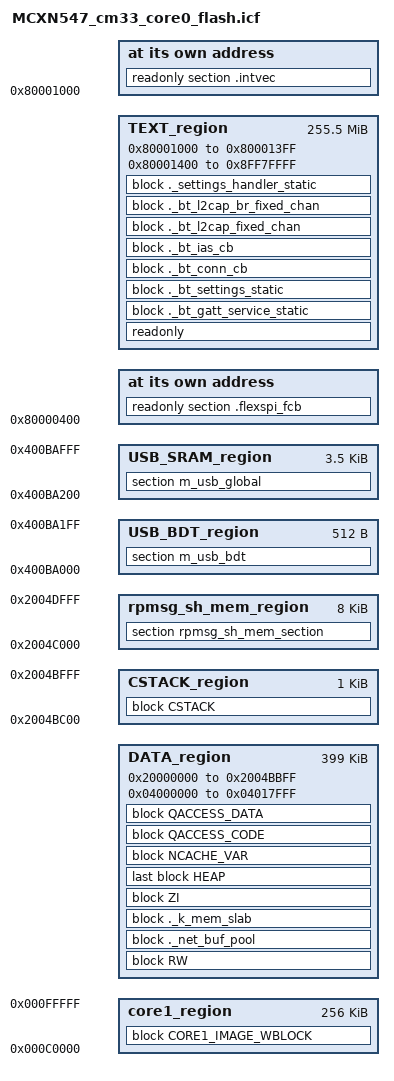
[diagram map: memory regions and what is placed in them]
/*
** ###################################################################
**     Processors:          MCXN547VDF_cm33_core0
**                          MCXN547VNL_cm33_core0
**
**     Compiler:            IAR ANSI C/C++ Compiler for ARM
**     Reference manual:    MCXNx4x Reference Manual
**     Version:             rev. 1.0, 2021-08-03
**     Build:               b230607
**
**     Abstract:
**         Linker file for the IAR ANSI C/C++ Compiler for ARM
**
**     Copyright 2016 Freescale Semiconductor, Inc.
**     Copyright 2016-2023 NXP
**     SPDX-License-Identifier: BSD-3-Clause
**
**     http:                 www.nxp.com
**     mail:                 support@nxp.com
**
** ###################################################################
*/


/* USB BDT size */
define symbol usb_bdt_size             = 0x200;
/* Stack and Heap Sizes */
if (isdefinedsymbol(__stack_size__)) {
  define symbol __size_cstack__        = __stack_size__;
} else {
  define symbol __size_cstack__        = 0x0400;
}

if (isdefinedsymbol(__heap_size__)) {
  define symbol __size_heap__          = __heap_size__;
} else {
  define symbol __size_heap__          = 0x1000;
}

define symbol LITTLEFS_REGION_SIZE               = 0x00080000;

if (isdefinedsymbol(__qspi_xip__)) {
  define symbol m_interrupts_start               = 0x80001000;
  define symbol m_interrupts_end                 = 0x800013FF;

  define symbol m_text_start                     = 0x80001400;
  define symbol m_text_end                       = 0x8FFFFFFF - LITTLEFS_REGION_SIZE;
} else {
  define symbol m_interrupts_start               = 0x00000000;
  define symbol m_interrupts_end                 = 0x000003FF;

  define symbol m_text_start                     = 0x00000400;
  define symbol m_text_end                       = 0x001FFFFF - LITTLEFS_REGION_SIZE;
}

define symbol m_boot_flash_conf_start          = 0x80000400;

/* NOTE: The last LITTLEFS_REGION_SIZE Flash( in range (m_text_end + 1) ~ (m_text_end + LITTLEFS_REGION_SIZE)) is reserved for litteFS data */

/*** littleFS configuration Start ***/
define exported symbol EDGEFAST_BT_LITTLEFS_STORAGE_START_ADDRESS = m_text_end + 1;
define exported symbol EDGEFAST_BT_LITTLEFS_STORAGE_SECTOR_SIZE   = 0x2000; /* 8k flash sector size */
define exported symbol EDGEFAST_BT_LITTLEFS_STORAGE_MAX_SECTORS   = LITTLEFS_REGION_SIZE / EDGEFAST_BT_LITTLEFS_STORAGE_SECTOR_SIZE;
/*** littleFS configuration End ***/

define symbol m_sramx_start                    = 0x04000000;
define symbol m_sramx_end                      = 0x04017FFF;

define exported symbol core1_image_start       = 0x000C0000;
define exported symbol core1_image_end         = 0x000FFFFF;

if (isdefinedsymbol(__use_shmem__)) {
  define symbol m_data_start                     = 0x20000000;
  define symbol m_data_end                       = 0x2004BFFF;
  define exported symbol rpmsg_sh_mem_start      = 0x2004C000;
  define exported symbol rpmsg_sh_mem_end        = 0x2004DFFF;
} else {
  define symbol m_data_start                     = 0x20000000;
  define symbol m_data_end                       = 0x2005FFFF;
}

define symbol m_usb_sram_start                 = 0x400BA000;
define symbol m_usb_sram_end                   = 0x400BAFFF;

define memory mem with size = 4G;

define region TEXT_region = mem:[from m_interrupts_start to m_interrupts_end]
                          | mem:[from m_text_start to m_text_end];
define region DATA_region = mem:[from m_data_start to m_data_end-__size_cstack__]
                          | mem:[from m_sramx_start to m_sramx_end];
define region CSTACK_region = mem:[from m_data_end-__size_cstack__+1 to m_data_end];
if (isdefinedsymbol(__use_shmem__)) {
  define region rpmsg_sh_mem_region     = mem:[from rpmsg_sh_mem_start to rpmsg_sh_mem_end];
}

define block CSTACK        with alignment = 8, size = __size_cstack__   { };
define block HEAP          with alignment = 8, size = __size_heap__     { };
define block RW            { readwrite };
define block ZI            { zi };
define block NCACHE_VAR    { section NonCacheable , section NonCacheable.init };
define block QACCESS_CODE  { section CodeQuickAccess };
define block QACCESS_DATA  { section DataQuickAccess };

define region core1_region = mem:[from core1_image_start to core1_image_end];
define block CORE1_IMAGE_WBLOCK          { section  __core1_image };

/* regions for USB */
define region USB_BDT_region = mem:[from m_usb_sram_start to m_usb_sram_start + usb_bdt_size - 1];
define region USB_SRAM_region = mem:[from m_usb_sram_start + usb_bdt_size to m_usb_sram_end];
place in USB_BDT_region                     { section m_usb_bdt };
place in USB_SRAM_region                    { section m_usb_global };

initialize by copy { readwrite, section .textrw, section CodeQuickAccess, section DataQuickAccess, object mflash_drv.o};

if (isdefinedsymbol(__USE_DLIB_PERTHREAD))
{
  /* Required in a multi-threaded application */
  initialize by copy with packing = none { section __DLIB_PERTHREAD };
}

do not initialize  { section .noinit, section m_usb_bdt, section m_usb_global };
if (isdefinedsymbol(__use_shmem__)) {
  do not initialize  { section rpmsg_sh_mem_section };
}

define block ._bt_gatt_service_static with fixed order { readonly section ._bt_gatt_service_static*};
define block ._bt_settings_static with fixed order { readonly section ._bt_settings*};
define block ._bt_conn_cb with fixed order { readonly section ._bt_conn_cb*};
define block ._bt_ias_cb with fixed order { readonly section ._bt_ias_cb*};
define block ._bt_l2cap_fixed_chan with fixed order { readonly section ._bt_l2cap_fixed_chan*};
define block ._bt_l2cap_br_fixed_chan with fixed order { readonly section ._bt_l2cap_br_fixed_chan*};
define block ._settings_handler_static with fixed order { readonly section ._settings_handler_static*};

define block ._k_mem_slab with fixed order { readwrite section ._k_mem_slab*};
define block ._net_buf_pool with fixed order { readwrite section ._net_buf_pool*};
keep{section .flexspi_fcb };
place at address mem: m_boot_flash_conf_start { readonly section .flexspi_fcb };
place at address mem: m_interrupts_start    { readonly section .intvec };
place in TEXT_region                        { readonly, block ._bt_gatt_service_static, block ._bt_settings_static, block ._bt_conn_cb, block ._bt_ias_cb, block ._bt_l2cap_fixed_chan, block ._bt_l2cap_br_fixed_chan, block ._settings_handler_static };
place in DATA_region                        { block RW, block ._net_buf_pool, block ._k_mem_slab };
place in DATA_region                        { block ZI };
place in DATA_region                        { last block HEAP };
place in CSTACK_region                      { block CSTACK };
place in DATA_region                        { block NCACHE_VAR };
place in DATA_region                        { block QACCESS_CODE };
place in DATA_region                        { block QACCESS_DATA };
if (isdefinedsymbol(__use_shmem__)) {
  place in rpmsg_sh_mem_region                { section rpmsg_sh_mem_section };
}
place in core1_region                       { block CORE1_IMAGE_WBLOCK };

keep { section .flash_area_list, section ._net_buf_pool*, section ._k_mem_slab*, section ._bt*, section ._settings*};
